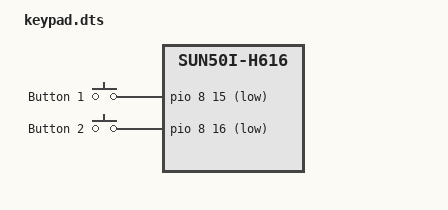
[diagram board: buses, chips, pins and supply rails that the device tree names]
/dts-v1/;
/plugin/;
/ {
    compatible = "allwinner,sun50i-h616";
    fragment@0 {
        target = <&pio>;
        __overlay__ {
            button_pins: button_pins {
		pins = "PI15", "PI16";
		function = "gpio_in";
                bias-pull-up;
            };
        };
    };
    fragment@1 {
        target-path = "/";
        __overlay__ {
            gpio_keys {
		compatible = "gpio-keys";
		pinctrl-names = "default";

		button1 {
			label = "Button 1";
			linux,code = <155>;
			gpios = <&pio 8 15 1>; // PI15
                        debounce-interval = <5>;
		};
                button2 {
                        label = "Button 2";
                        linux,code = <156>;
                        gpios = <&pio 8 16 1>; // PI16
                        debounce-interval = <5>;
		};
            };
        };
    };
}; 
